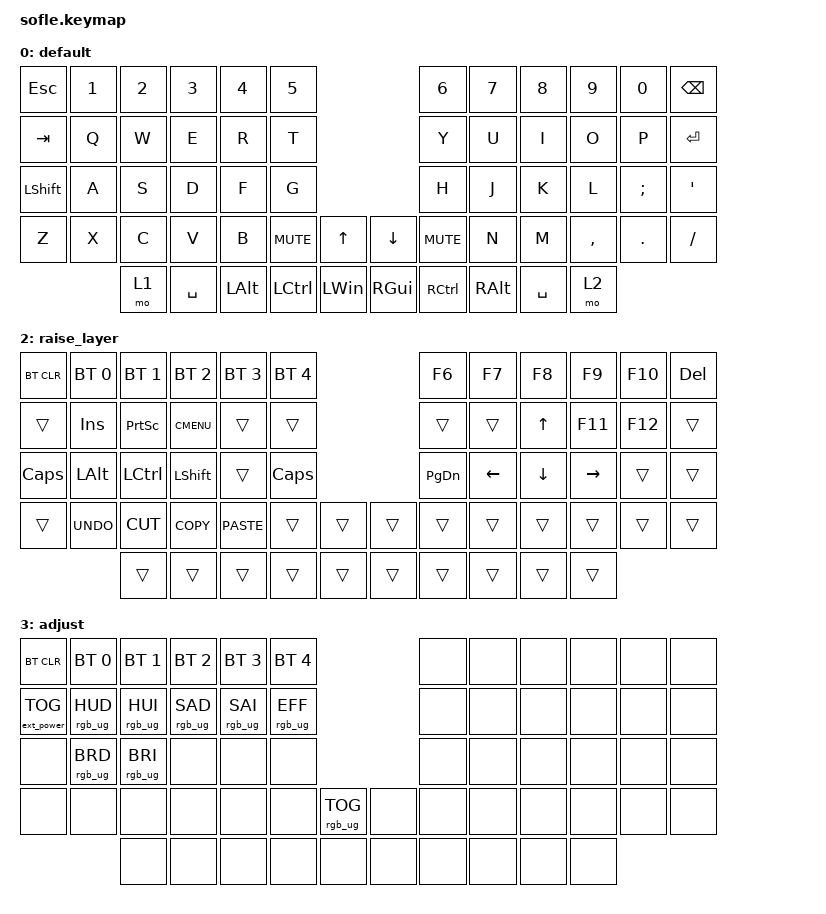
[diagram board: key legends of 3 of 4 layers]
/*
 * Copyright (c) 2020 The ZMK Contributors
 *
 * SPDX-License-Identifier: MIT
 */

#include <behaviors.dtsi>
#include <dt-bindings/zmk/keys.h>
#include <dt-bindings/zmk/bt.h>
#include <dt-bindings/zmk/rgb.h>
#include <dt-bindings/zmk/ext_power.h>

//For RGB support https://github.com/zmkfirmware/zmk/issues/885
#include <../boards/shields/kyria/boards/nice_nano.overlay>

#define BASE 0
#define LOWER 1
#define RAISE 2
#define ADJUST 3

// 以下的代码用来降低旋转分辨率

&left_encoder {
    resolution = <4>;
};

&right_encoder {
    resolution = <4>;
};


/*
 * Temporarily here because nice nano v2 spi is not defined on ZMK Yet
 * Source: https://github.com/zmkfirmware/zmk/blob/main/app/boards/shields/reviung41/boards/nice_nano.overlay
 * GitHub Issue: https://github.com/zmkfirmware/zmk/issues/885
 */

#include <dt-bindings/led/led.h>

&pinctrl {
    spi3_default: spi3_default {
        group1 {
            psels = <NRF_PSEL(SPIM_MOSI, 0, 22)>;
        };
    };

    spi3_sleep: spi3_sleep {
        group1 {
            psels = <NRF_PSEL(SPIM_MOSI, 0, 22)>;
            low-power-enable;
        };
    };
};

&spi3 {
    compatible = "nordic,nrf-spim";
    status = "okay";

    pinctrl-0 = <&spi3_default>;
    pinctrl-1 = <&spi3_sleep>;
    pinctrl-names = "default", "sleep";

    led_strip: ws2812@0 {
        compatible = "worldsemi,ws2812-spi";
        label = "WS2812";

        /* SPI */
        reg = <0>; /* ignored, but necessary for SPI bindings */
        spi-max-frequency = <4000000>;

        /* WS2812 */
        chain-length = <30>;
        spi-one-frame = <0x70>;
        spi-zero-frame = <0x40>;

        color-mapping = <LED_COLOR_ID_GREEN LED_COLOR_ID_RED LED_COLOR_ID_BLUE>;
    };
};

/ {
    chosen {
        zmk,underglow = &led_strip;
    };
};

/* END temporary RGB support section */

/ {

   // Activate ADJUST layer by pressing raise and lower
    conditional_layers {
        compatible = "zmk,conditional-layers";
        adjust_layer {
            if-layers = <LOWER RAISE>;
            then-layer = <ADJUST>;
        };
    };

    keymap {
        compatible = "zmk,keymap";

        default_layer {
            display-name = "default";
            bindings = <
  &kp ESC  &kp N1  &kp N2     &kp N3    &kp N4      &kp N5                              &kp N6    &kp N7     &kp N8     &kp N9    &kp N0  &kp BACKSPACE
  &kp TAB   &kp Q   &kp W      &kp E     &kp R       &kp T                               &kp Y     &kp U      &kp I      &kp O     &kp P      &kp ENTER
&kp LSHFT   &kp A   &kp S      &kp D     &kp F       &kp G                               &kp H     &kp J      &kp K      &kp L  &kp SEMI        &kp SQT
    &kp Z   &kp X   &kp C      &kp V     &kp B  &kp C_MUTE        &kp UP  &kp DOWN  &kp C_MUTE     &kp N      &kp M  &kp COMMA   &kp DOT      &kp SLASH
                    &mo 1  &kp SPACE  &kp LALT   &kp LCTRL  &kp LEFT_WIN  &kp RGUI   &kp RCTRL  &kp RALT  &kp SPACE      &mo 2
            >;

            sensor-bindings = <&inc_dec_kp LEFT RIGHT &inc_dec_kp C_VOL_DN C_VOL_UP>;
        };

        lower_layer {
            display-name = "lower";
            bindings = <
&trans     &kp F1     &kp F2     &kp F3       &kp F4    &kp F5                              &rgb_ug RGB_EFF    &kp KP_NUMBER_7  &kp KP_NUMBER_8  &kp KP_NUMBER_9  &kp MINUS         &kp EQUAL
&kp GRAVE  &kp N1     &kp N2     &kp N3       &kp N4    &kp N5                              &ext_power EP_TOG  &kp KP_NUMBER_4  &kp KP_NUMBER_5  &kp KP_NUMBER_6  &kp LEFT_BRACKET  &trans
&trans     &kp EXCL   &kp AT     &kp HASH     &kp DLLR  &kp PRCNT                           &bt BT_CLR         &kp KP_NUMBER_1  &kp KP_NUMBER_2  &kp KP_NUMBER_3  &kp RBKT          &kp PIPE
&trans     &kp EQUAL  &kp MINUS  &kp KP_PLUS  &kp LBRC  &kp RBRC   &trans  &rgb_ug RGB_BRI  &rgb_ug RGB_TOG    &bt BT_SEL 0     &bt BT_SEL 1     &kp KP_NUMBER_0  &trans            &bootloader
                      &trans     &trans       &trans    &trans     &trans  &trans           &bt BT_SEL 2       &rgb_ug RGB_BRD  &trans
            >;

            sensor-bindings = <&inc_dec_kp C_VOL_UP C_VOL_DN &inc_dec_kp PG_UP PG_DN>;
        };

        raise_layer {
            bindings = <
&bt BT_CLR    &bt BT_SEL 0  &bt BT_SEL 1  &bt BT_SEL 2  &bt BT_SEL 3  &bt BT_SEL 4                  &kp F6     &kp F7    &kp F8    &kp F9     &kp F10  &kp DEL
&trans        &kp INS       &kp PSCRN     &kp K_CMENU   &trans        &trans                        &trans     &trans    &kp UP    &kp F11    &kp F12  &trans
&kp CAPSLOCK  &kp LALT      &kp LCTRL     &kp LSHFT     &trans        &kp CLCK                      &kp PG_DN  &kp LEFT  &kp DOWN  &kp RIGHT  &trans   &trans
&trans        &kp K_UNDO    &kp K_CUT     &kp K_COPY    &kp K_PASTE   &trans        &trans  &trans  &trans     &trans    &trans    &trans     &trans   &trans
                            &trans        &trans        &trans        &trans        &trans  &trans  &trans     &trans    &trans    &trans
            >;

            sensor-bindings = <&inc_dec_kp C_VOL_UP C_VOL_DN &inc_dec_kp PG_UP PG_DN>;
        };

        adjust_layer {
            display-name = "adjust";
            bindings = <
&bt BT_CLR        &bt BT_SEL 0    &bt BT_SEL 1    &bt BT_SEL 2    &bt BT_SEL 3    &bt BT_SEL 4                            &none &none &none &none &none &none
&ext_power EP_TOG &rgb_ug RGB_HUD &rgb_ug RGB_HUI &rgb_ug RGB_SAD &rgb_ug RGB_SAI &rgb_ug RGB_EFF                         &none &none &none &none &none &none
&none             &rgb_ug RGB_BRD &rgb_ug RGB_BRI &none           &none           &none                                   &none &none &none &none &none &none
&none             &none           &none           &none           &none           &none            &rgb_ug RGB_TOG &none  &none &none &none &none &none &none
                                  &none           &none           &none           &none            &none           &none  &none &none &none &none
            >;
        };

    };
};
